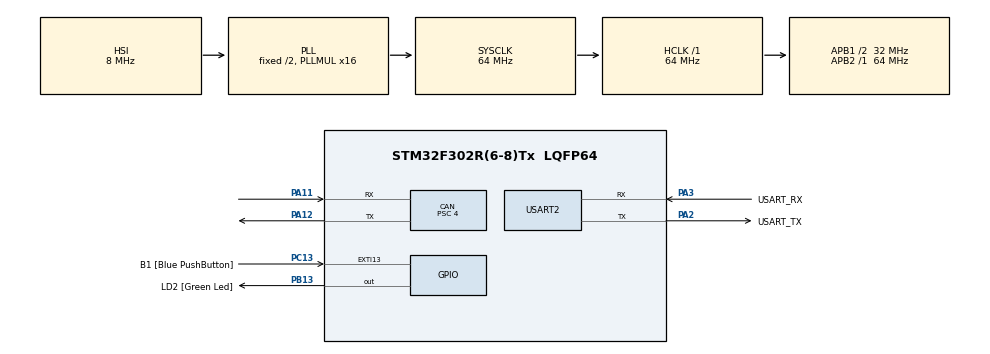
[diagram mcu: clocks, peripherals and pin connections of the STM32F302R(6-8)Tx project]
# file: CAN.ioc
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CAN.ABOM=ENABLE
CAN.AWUM=ENABLE
CAN.BS1=CAN_BS1_13TQ
CAN.BS2=CAN_BS2_2TQ
CAN.CalculateTimeQuantum=125.0
CAN.Mode=CAN_MODE_LOOPBACK
CAN.NART=ENABLE
CAN.Prescaler=4
CAN.RFLM=ENABLE
CAN.SJW=CAN_SJW_4TQ
CAN.TXFP=ENABLE
Mcu.Family=STM32F3
Mcu.Name=STM32F302R(6-8)Tx
Mcu.Package=LQFP64
NVIC.CAN_RX1_IRQn=true\:0\:0\:false\:false\:true\:true
NVIC.PriorityGroup=NVIC_PRIORITYGROUP_0
NVIC.USB_HP_CAN_TX_IRQn=true\:0\:0\:false\:false\:true\:true
NVIC.USB_LP_CAN_RX0_IRQn=true\:0\:0\:false\:false\:true\:true
PA11.Mode=Master
PA11.Signal=CAN_RX
PA12.Mode=Master
PA12.Signal=CAN_TX
PA13.Mode=Serial_Wire
PA13.Signal=SYS_JTMS-SWDIO
PA14.GPIO_Label=TCK
PA14.Mode=Serial_Wire
PA14.Signal=SYS_JTCK-SWCLK
PA2.GPIO_Label=USART_TX
PA2.GPIO_Mode=GPIO_MODE_AF_PP
PA2.GPIO_PuPd=GPIO_NOPULL
PA2.GPIO_Speed=GPIO_SPEED_FREQ_LOW
PA2.Mode=Asynchronous
PA2.Signal=USART2_TX
PA3.GPIO_Label=USART_RX
PA3.GPIO_Mode=GPIO_MODE_AF_PP
PA3.GPIO_PuPd=GPIO_NOPULL
PA3.GPIO_Speed=GPIO_SPEED_FREQ_LOW
PA3.Mode=Asynchronous
PA3.Signal=USART2_RX
PB13.GPIO_Label=LD2 [Green Led]
PB13.Signal=GPIO_Output
PB3.Signal=SYS_JTDO-TRACESWO
PC13.GPIO_Label=B1 [Blue PushButton]
PC13.GPIO_ModeDefaultEXTI=GPIO_MODE_IT_FALLING
PC13.Signal=GPXTI13
PC14\ -\ OSC32_IN.Mode=LSE-External-Oscillator
PC14\ -\ OSC32_IN.Signal=RCC_OSC32_IN
PC15\ -\ OSC32_OUT.Mode=LSE-External-Oscillator
PC15\ -\ OSC32_OUT.Signal=RCC_OSC32_OUT
PF0-OSC_IN.Mode=HSE-External-Clock-Source
PF0-OSC_IN.Signal=RCC_OSC_IN
PF1-OSC_OUT.Signal=RCC_OSC_OUT
ProjectManager.HeapSize=0x200
ProjectManager.StackSize=0x400
ProjectManager.TargetToolchain=MDK-ARM V5
RCC.AHBFreq_Value=64000000
RCC.APB1CLKDivider=RCC_HCLK_DIV2
RCC.APB1Freq_Value=32000000
RCC.APB1TimFreq_Value=64000000
RCC.APB2Freq_Value=64000000
RCC.APB2TimFreq_Value=64000000
RCC.CortexFreq_Value=64000000
RCC.HCLKFreq_Value=64000000
RCC.HSE_VALUE=8000000
RCC.HSI_VALUE=8000000
RCC.PLLM=8
RCC.PLLMUL=RCC_PLL_MUL16
RCC.PLLN=336
RCC.PLLP=RCC_PLLP_DIV4
RCC.PLLQ=7
RCC.RCC_PLLsource_Clock_Source_FROM_HSE=RCC_HSE_PREDIV_DIV2
RCC.SYSCLKFreq_VALUE=64000000
RCC.SYSCLKSourceVirtual=RCC_SYSCLKSOURCE_PLLCLK
RCC.USBFreq_Value=64000000
USART2.VirtualMode-Asynchronous=VM_ASYNC
board=NUCLEO-F302R8

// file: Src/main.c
/* USER CODE BEGIN Header */
/**
  ******************************************************************************
  * @file           : main.c
  * @brief          : Main program body
  ******************************************************************************
  ** This notice applies to any and all portions of this file
  * that are not between comment pairs USER CODE BEGIN and
  * USER CODE END. Other portions of this file, whether
  * inserted by the user or by software development tools
  * are owned by their respective copyright owners.
  *
  * COPYRIGHT(c) 2018 STMicroelectronics
  *
  * Redistribution and use in source and binary forms, with or without modification,
  * are permitted provided that the following conditions are met:
  *   1. Redistributions of source code must retain the above copyright notice,
  *      this list of conditions and the following disclaimer.
  *   2. Redistributions in binary form must reproduce the above copyright notice,
  *      this list of conditions and the following disclaimer in the documentation
  *      and/or other materials provided with the distribution.
  *   3. Neither the name of STMicroelectronics nor the names of its contributors
  *      may be used to endorse or promote products derived from this software
  *      without specific prior written permission.
  *
  * THIS SOFTWARE IS PROVIDED BY THE COPYRIGHT HOLDERS AND CONTRIBUTORS "AS IS"
  * AND ANY EXPRESS OR IMPLIED WARRANTIES, INCLUDING, BUT NOT LIMITED TO, THE
  * IMPLIED WARRANTIES OF MERCHANTABILITY AND FITNESS FOR A PARTICULAR PURPOSE ARE
  * DISCLAIMED. IN NO EVENT SHALL THE COPYRIGHT HOLDER OR CONTRIBUTORS BE LIABLE
  * FOR ANY DIRECT, INDIRECT, INCIDENTAL, SPECIAL, EXEMPLARY, OR CONSEQUENTIAL
  * DAMAGES (INCLUDING, BUT NOT LIMITED TO, PROCUREMENT OF SUBSTITUTE GOODS OR
  * SERVICES; LOSS OF USE, DATA, OR PROFITS; OR BUSINESS INTERRUPTION) HOWEVER
  * CAUSED AND ON ANY THEORY OF LIABILITY, WHETHER IN CONTRACT, STRICT LIABILITY,
  * OR TORT (INCLUDING NEGLIGENCE OR OTHERWISE) ARISING IN ANY WAY OUT OF THE USE
  * OF THIS SOFTWARE, EVEN IF ADVISED OF THE POSSIBILITY OF SUCH DAMAGE.
  *
  ******************************************************************************
  */
/* USER CODE END Header */

#include "main.h"

/* USER CODE BEGIN Includes */
#include "SharedCan.h"
/* USER CODE END Includes */

CAN_HandleTypeDef hcan;

UART_HandleTypeDef huart2;

void SystemClock_Config(void);
static void MX_GPIO_Init(void);
static void MX_CAN_Init(void);
static void MX_USART2_UART_Init(void);

int main(void)
{

  /* MCU Configuration--------------------------------------------------------*/

  /* Reset of all peripherals, Initializes the Flash interface and the Systick. */
  HAL_Init();

  /* Configure the system clock */
  SystemClock_Config();

  /* Initialize all configured peripherals */
  MX_GPIO_Init();
  MX_CAN_Init();
  MX_USART2_UART_Init();

  /* Infinite loop */
  /* USER CODE BEGIN WHILE */

  float test_float = 3.1415926;
  uint8_t test_data_lut[CAN_PAYLOAD_SIZE] = {0x1, 0x2, 0x3, 0x4, 0xA, 0xB, 0xC, 0xD};
  while (1)
  {
    /* USER CODE END WHILE */

    /* USER CODE BEGIN 3 */
    for (uint32_t i = 0; i < sizeof(test_data_lut) / sizeof(test_data_lut[0]); i++)
    {
    // TODO: Send two floats in one CAN message
    //SharedCan_TransmitDataCAN(&can_headers[BMS_HEARTBEAT], uint8_t * data)
      // TODO:
      SharedCan_TransmitDataCan(DCM_ERROR_STDID, DCM_ERROR_DLC, &test_data_lut[0]);
      HAL_Delay(10);
    }

  }

  /* USER CODE END 3 */
}

void SystemClock_Config(void)
{
  RCC_OscInitTypeDef RCC_OscInitStruct = {0};
  RCC_ClkInitTypeDef RCC_ClkInitStruct = {0};

  /**Initializes the CPU, AHB and APB busses clocks
  */
  RCC_OscInitStruct.OscillatorType = RCC_OSCILLATORTYPE_HSI;
  RCC_OscInitStruct.HSIState = RCC_HSI_ON;
  RCC_OscInitStruct.HSICalibrationValue = RCC_HSICALIBRATION_DEFAULT;
  RCC_OscInitStruct.PLL.PLLState = RCC_PLL_ON;
  RCC_OscInitStruct.PLL.PLLSource = RCC_PLLSOURCE_HSI;
  RCC_OscInitStruct.PLL.PLLMUL = RCC_PLL_MUL16;
  if (HAL_RCC_OscConfig(&RCC_OscInitStruct) != HAL_OK)
  {
    Error_Handler();
  }
  /**Initializes the CPU, AHB and APB busses clocks
  */
  RCC_ClkInitStruct.ClockType = RCC_CLOCKTYPE_HCLK|RCC_CLOCKTYPE_SYSCLK
                              |RCC_CLOCKTYPE_PCLK1|RCC_CLOCKTYPE_PCLK2;
  RCC_ClkInitStruct.SYSCLKSource = RCC_SYSCLKSOURCE_PLLCLK;
  RCC_ClkInitStruct.AHBCLKDivider = RCC_SYSCLK_DIV1;
  RCC_ClkInitStruct.APB1CLKDivider = RCC_HCLK_DIV2;
  RCC_ClkInitStruct.APB2CLKDivider = RCC_HCLK_DIV1;

  if (HAL_RCC_ClockConfig(&RCC_ClkInitStruct, FLASH_LATENCY_2) != HAL_OK)
  {
    Error_Handler();
  }
}

static void MX_CAN_Init(void)
{

  hcan.Instance = CAN;
  hcan.Init.Prescaler = 4;
  hcan.Init.Mode = CAN_MODE_LOOPBACK;
  hcan.Init.SyncJumpWidth = CAN_SJW_4TQ;
  hcan.Init.TimeSeg1 = CAN_BS1_13TQ;
  hcan.Init.TimeSeg2 = CAN_BS2_2TQ;
  hcan.Init.TimeTriggeredMode = DISABLE;
  hcan.Init.AutoBusOff = ENABLE;
  hcan.Init.AutoWakeUp = ENABLE;
  hcan.Init.AutoRetransmission = ENABLE;
  hcan.Init.ReceiveFifoLocked = ENABLE;
  hcan.Init.TransmitFifoPriority = ENABLE;
  if (HAL_CAN_Init(&hcan) != HAL_OK)
  {
    Error_Handler();
  }
  /* USER CODE BEGIN CAN_Init 2 */

  if (SharedCan_StartCanInInterruptMode(&hcan) != HAL_OK)
  {
    Error_Handler();
  }

  /* USER CODE END CAN_Init 2 */

}

static void MX_USART2_UART_Init(void)
{

  huart2.Instance = USART2;
  huart2.Init.BaudRate = 38400;
  huart2.Init.WordLength = UART_WORDLENGTH_8B;
  huart2.Init.StopBits = UART_STOPBITS_1;
  huart2.Init.Parity = UART_PARITY_NONE;
  huart2.Init.Mode = UART_MODE_TX_RX;
  huart2.Init.HwFlowCtl = UART_HWCONTROL_NONE;
  huart2.Init.OverSampling = UART_OVERSAMPLING_16;
  huart2.Init.OneBitSampling = UART_ONE_BIT_SAMPLE_DISABLE;
  huart2.AdvancedInit.AdvFeatureInit = UART_ADVFEATURE_NO_INIT;
  if (HAL_UART_Init(&huart2) != HAL_OK)
  {
    Error_Handler();
  }

}

static void MX_GPIO_Init(void)
{
  GPIO_InitTypeDef GPIO_InitStruct = {0};

  /* GPIO Ports Clock Enable */
  __HAL_RCC_GPIOC_CLK_ENABLE();
  __HAL_RCC_GPIOF_CLK_ENABLE();
  __HAL_RCC_GPIOA_CLK_ENABLE();
  __HAL_RCC_GPIOB_CLK_ENABLE();

  /*Configure GPIO pin Output Level */
  HAL_GPIO_WritePin(LD2_GPIO_Port, LD2_Pin, GPIO_PIN_RESET);

  /*Configure GPIO pin : B1_Pin */
  GPIO_InitStruct.Pin = B1_Pin;
  GPIO_InitStruct.Mode = GPIO_MODE_IT_FALLING;
  GPIO_InitStruct.Pull = GPIO_NOPULL;
  HAL_GPIO_Init(B1_GPIO_Port, &GPIO_InitStruct);

  /*Configure GPIO pin : LD2_Pin */
  GPIO_InitStruct.Pin = LD2_Pin;
  GPIO_InitStruct.Mode = GPIO_MODE_OUTPUT_PP;
  GPIO_InitStruct.Pull = GPIO_NOPULL;
  GPIO_InitStruct.Speed = GPIO_SPEED_FREQ_LOW;
  HAL_GPIO_Init(LD2_GPIO_Port, &GPIO_InitStruct);

}

void Error_Handler(void)
{
}

/************************ (C) COPYRIGHT STMicroelectronics *****END OF FILE****/
